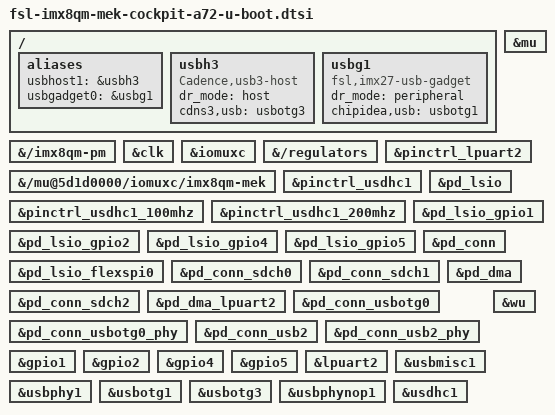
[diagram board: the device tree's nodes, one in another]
// SPDX-License-Identifier: GPL-2.0+
/*
 * Copyright 2020 NXP
 */

/ {

	aliases {
		usbhost1 = &usbh3;
		usbgadget0 = &usbg1;
	};

	usbh3: usbh3 {
		compatible = "Cadence,usb3-host";
		dr_mode = "host";
		cdns3,usb = <&usbotg3>;
		status = "okay";
	};

	usbg1: usbg1 {
		compatible = "fsl,imx27-usb-gadget";
		dr_mode = "peripheral";
		chipidea,usb = <&usbotg1>;
		status = "okay";
		u-boot,dm-spl;
	};
};

&{/imx8qm-pm} {

	u-boot,dm-spl;
};

&mu {
	u-boot,dm-spl;
};

&clk {
	u-boot,dm-spl;
};

&iomuxc {
	u-boot,dm-spl;
};

&{/regulators} {
	u-boot,dm-spl;
};

&{/mu@5d1d0000/iomuxc/imx8qm-mek} {
	u-boot,dm-spl;
};

&pinctrl_lpuart2 {
	u-boot,dm-spl;
};

&pinctrl_usdhc1 {
	u-boot,dm-spl;
};

&pinctrl_usdhc1_100mhz {
	u-boot,dm-spl;
};

&pinctrl_usdhc1_200mhz {
	u-boot,dm-spl;
};

&pd_lsio {
	u-boot,dm-spl;
};

&pd_lsio_gpio1 {
	u-boot,dm-spl;
};

&pd_lsio_gpio2 {
	u-boot,dm-spl;
};

&pd_lsio_gpio4 {
	u-boot,dm-spl;
};

&pd_lsio_gpio5 {
	u-boot,dm-spl;
};

&pd_lsio_flexspi0 {
	u-boot,dm-spl;
};

&pd_conn {
	u-boot,dm-spl;
};

&pd_conn_sdch0 {
	u-boot,dm-spl;
};

&pd_conn_sdch1 {
	u-boot,dm-spl;
};

&pd_conn_sdch2 {
	u-boot,dm-spl;
};

&pd_dma {
	u-boot,dm-spl;
};

&pd_dma_lpuart2 {
	u-boot,dm-spl;
};

&pd_conn_usbotg0 {
	u-boot,dm-spl;
};

&pd_conn_usbotg0_phy {
	u-boot,dm-spl;
};

&pd_conn_usb2 {
	u-boot,dm-spl;
};

&pd_conn_usb2_phy {
	u-boot,dm-spl;
};

&gpio1 {
	u-boot,dm-spl;
};

&gpio2 {
	u-boot,dm-spl;
};

&gpio4 {
	u-boot,dm-spl;
};

&gpio5 {
	u-boot,dm-spl;
};

&lpuart2 {
	u-boot,dm-spl;
};

&usbmisc1 {
	u-boot,dm-spl;
};

&usbphy1 {
	u-boot,dm-spl;
};

&usbotg1 {
	u-boot,dm-spl;
};

&usbotg3 {
	u-boot,dm-spl;
};

&usbphynop1 {
	u-boot,dm-spl;
};

&usdhc1 {
	u-boot,dm-spl;
};

&wu {
	u-boot,dm-spl;
};
